VERSION ""

NS_ :

BS_:

BU_: Rear_Node Front_Node Display_Screen Body_Orientation
VAL_TABLE_ Logger_Status 1 "End" 0 "Begin" ;

BO_ 151 Rear_Wheel_Speeds: 8 Rear_Node
 SG_ RR_Wheelspeed_rpm : 16|16@1+ (0.1,0) [0|6553.5] "rpm"  Display_Screen
 SG_ RL_Wheelspeed_rpm : 0|16@1+ (0.1,0) [0|6553.5] "rpm"  Display_Screen

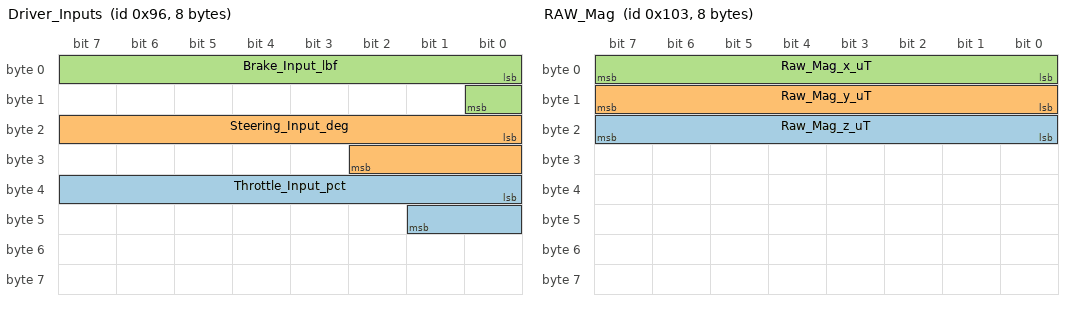
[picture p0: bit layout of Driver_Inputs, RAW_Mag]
BO_ 150 Driver_Inputs: 8 Front_Node
 SG_ Throttle_Input_pct : 32|10@1+ (0.1,0) [0|102.3] "percent" Vector__XXX
 SG_ Steering_Input_deg : 16|11@1- (1,0) [-1024|1023] "deg"  Display_Screen
 SG_ Brake_Input_lbf : 0|9@1+ (1,0) [0|511] "lbf"  Display_Screen

BO_ 152 Front_Wheel_Speeds: 8 Front_Node
 SG_ FR_Wheelspeed_rpm : 16|16@1+ (0.1,0) [0|6553.5] "rpm"  Display_Screen
 SG_ FL_Wheelspeed_rpm : 0|16@1+ (0.1,0) [0|6553.5] "rpm"  Display_Screen

BO_ 153 Brake_Pressures: 8 Front_Node
 SG_ FR_Press_psi : 16|16@1- (0.1,0) [-3276.8|3276.7] "psi"  Display_Screen
 SG_ FL_Press_psi : 0|16@1- (0.1,0) [-3276.8|3276.7] "psi"  Display_Screen

BO_ 260 CAN_Logger_End: 8 Display_Screen
 SG_ CAN_Logger : 0|1@1+ (1,0) [0|1] "" Vector__XXX

BO_ 261 CAN_Logger_Begin: 8 Display_Screen
 SG_ CAN_Logger : 0|1@1+ (1,0) [0|1] "" Vector__XXX

BO_ 259 RAW_Mag: 8 Body_Orientation
 SG_ Raw_Mag_z_uT : 16|8@1- (1,0) [-128|127] "uTesla"  Display_Screen
 SG_ Raw_Mag_y_uT : 8|8@1- (1,0) [-128|127] "uTesla"  Display_Screen
 SG_ Raw_Mag_x_uT : 0|8@1- (1,0) [-128|127] "uTesla"  Display_Screen

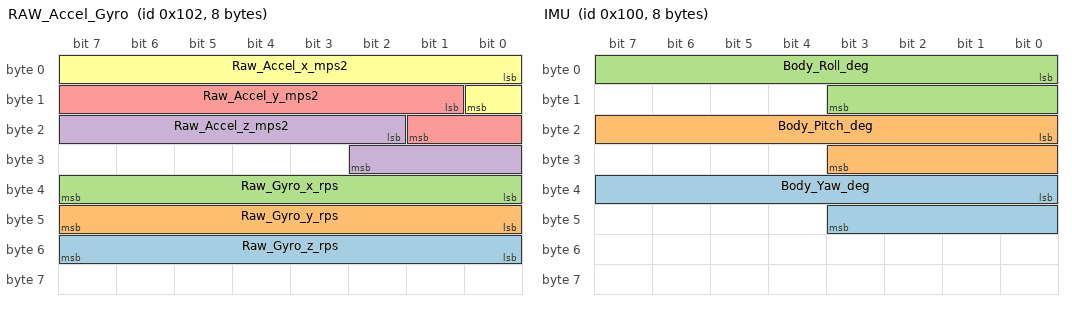
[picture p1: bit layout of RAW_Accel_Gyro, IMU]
BO_ 258 RAW_Accel_Gyro: 8 Body_Orientation
 SG_ Raw_Gyro_z_rps : 48|8@1- (0.1,0) [-12.8|12.7] "rad/s"  Display_Screen
 SG_ Raw_Gyro_y_rps : 40|8@1- (0.1,0) [-12.8|12.7] "rad/s"  Display_Screen
 SG_ Raw_Gyro_x_rps : 32|8@1- (0.1,0) [-12.8|12.7] "rad/s"  Display_Screen
 SG_ Raw_Accel_z_mps2 : 18|9@1- (0.1,0) [-25.6|25.5] "m/s^2"  Display_Screen
 SG_ Raw_Accel_y_mps2 : 9|9@1- (0.1,0) [-25.6|25.5] "m/s^2"  Display_Screen
 SG_ Raw_Accel_x_mps2 : 0|9@1- (0.1,0) [-25.6|25.5] "m/s^2"  Display_Screen

BO_ 257 GPS: 8 Body_Orientation
 SG_ True_Yaw_deg : 16|12@1+ (0.1,0) [0|409.5] "deg" Vector__XXX
 SG_ Body_Speed_mps : 0|16@1+ (0.1,0) [0|6553.5] "m/s"  Display_Screen

BO_ 256 IMU: 8 Body_Orientation
 SG_ Body_Yaw_deg : 32|12@1+ (0.1,0) [0|409.5] "deg"  Display_Screen
 SG_ Body_Pitch_deg : 16|12@1+ (0.1,0) [0|409.5] "deg"  Display_Screen
 SG_ Body_Roll_deg : 0|12@1+ (0.1,0) [0|409.5] "deg"  Display_Screen

CM_ SG_ 150 Throttle_Input_pct "Normalized, goes from 0 to 100%
Resolution of 0.1 for smoother reading of input";
CM_ SG_ 259 Raw_Mag_z_uT "Raw magnetic field data from magnetometer (microTesla)
z-Axis";
CM_ SG_ 259 Raw_Mag_y_uT "Raw magnetic field data from magnetometer (microTesla)
y-Axis";
CM_ SG_ 259 Raw_Mag_x_uT "Raw magnetic field data from magnetometer (microTesla)
x-Axis";
CM_ SG_ 258 Raw_Gyro_z_rps "Raw angular velocity data from gyroscope (rad/s)
z-Axis";
CM_ SG_ 258 Raw_Gyro_y_rps "Raw angular velocity data from gyroscope (rad/s)
y-Axis";
CM_ SG_ 258 Raw_Gyro_x_rps "Raw angular velocity data from gyroscope (rad/s)
x-Axis";
CM_ SG_ 258 Raw_Accel_z_mps2 "Raw acceleration data from the accelerometer (m/s^2)
z-Axis";
CM_ SG_ 258 Raw_Accel_y_mps2 "Raw acceleration data from the accelerometer (m/s^2)
y-Axis";
CM_ SG_ 258 Raw_Accel_x_mps2 "Raw acceleration data from the accelerometer (m/s^2)
x-Axis";
CM_ SG_ 257 True_Yaw_deg "Yaw angle of the vehicle body in degrees

Output is an integer to save space

Resolution of 0.1 degrees";
CM_ SG_ 257 Body_Speed_mps "Velocity of the vehicle body in m/s

Resolution of 0.1 m/s (0.224 mph)";
CM_ SG_ 256 Body_Yaw_deg "Yaw angle of the vehicle body in degrees

Output is an integer to save space

Resolution of 0.1 degrees";
CM_ SG_ 256 Body_Pitch_deg "Pitch angle of the vehicle body in degrees

Output is an integer to save space

Resolution of 0.1 degrees";
CM_ SG_ 256 Body_Roll_deg "Roll angle of the vehicle body in degrees

Output is an integer to save space

Resolution of 0.1 degrees";
BA_DEF_  "BusType" STRING ;
BA_DEF_DEF_  "BusType" "CAN";
